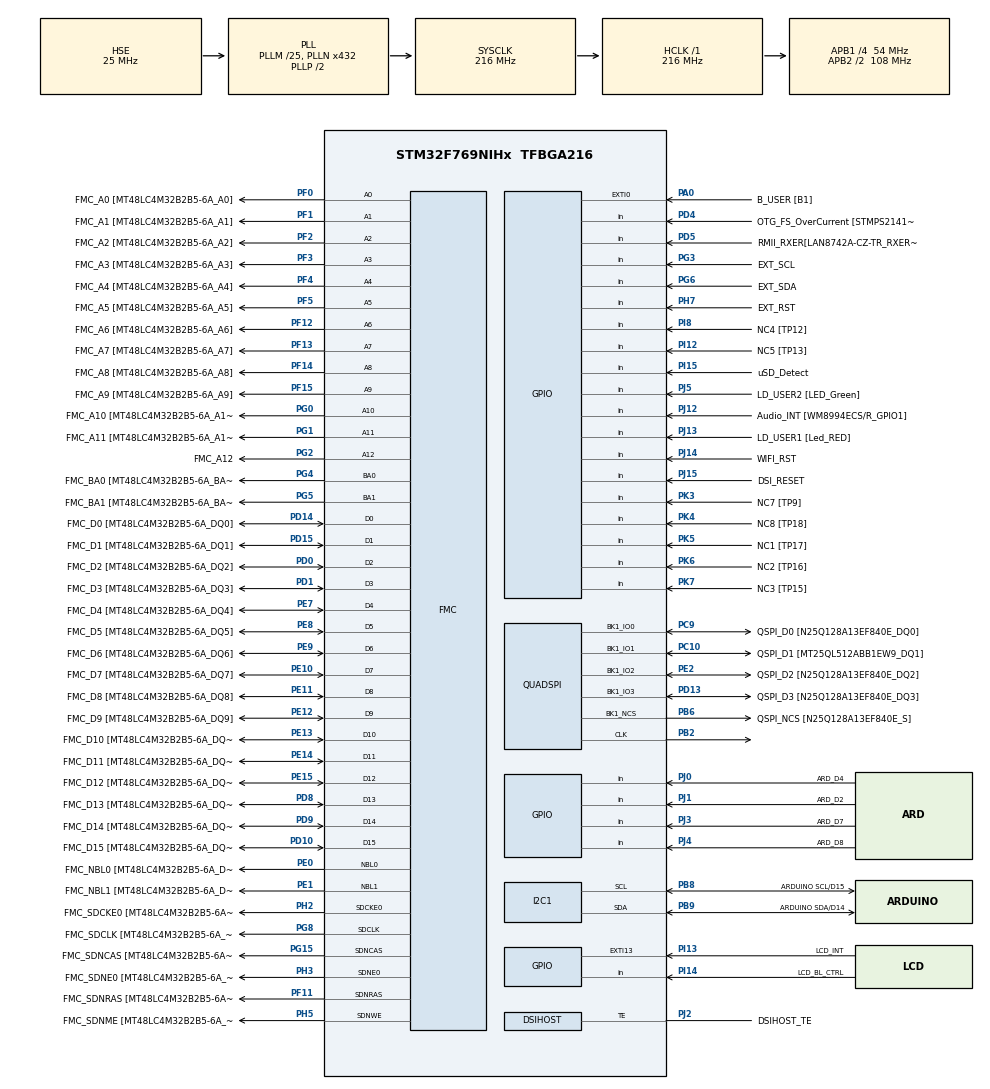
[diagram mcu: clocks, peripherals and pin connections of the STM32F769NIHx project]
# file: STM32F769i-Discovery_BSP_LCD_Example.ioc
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CORTEX_M7.ART_ACCLERATOR_ENABLE=1
CORTEX_M7.CPU_ICache=Enabled
DSIHOST.AcknowledgeRequest=DSI_ACKNOWLEDGE_ENABLE
DSIHOST.CommandSize=800
DSIHOST_CKN.GPIO_Label=DSI_CK_N
DSIHOST_CKN.Mode=DSIHost_Adapted_TE
DSIHOST_CKN.Signal=DSIHOST_CKN
DSIHOST_CKP.GPIO_Label=DSI_CK_P
DSIHOST_CKP.Mode=DSIHost_Adapted_TE
DSIHOST_CKP.Signal=DSIHOST_CKP
DSIHOST_D0N.GPIO_Label=DSI_D0_N
DSIHOST_D0N.Mode=DSIHost_Adapted_TE
DSIHOST_D0N.Signal=DSIHOST_D0N
DSIHOST_D0P.GPIO_Label=DSI_D0_p
DSIHOST_D0P.Mode=DSIHost_Adapted_TE
DSIHOST_D0P.Signal=DSIHOST_D0P
DSIHOST_D1N.GPIO_Label=DSI_D1_N
DSIHOST_D1N.Mode=DSIHost_Adapted_TE
DSIHOST_D1N.Signal=DSIHOST_D1N
DSIHOST_D1P.GPIO_Label=DSI_D1_P
DSIHOST_D1P.Mode=DSIHost_Adapted_TE
DSIHOST_D1P.Signal=DSIHOST_D1P
I2C1.Timing=0x20404768
LTDC.Alpha0_L0=255
LTDC.Alpha0_L1=255
LTDC.WindowX1_L0=800
LTDC.WindowX1_L1=800
LTDC.WindowY1_L0=480
LTDC.WindowY1_L1=480
Mcu.Family=STM32F7
Mcu.Name=STM32F769NIHx
Mcu.Package=TFBGA216
NVIC.EXTI0_IRQn=true\:0\:0\:false\:false\:true\:true\:true
NVIC.PriorityGroup=NVIC_PRIORITYGROUP_4
NVIC.TIM6_DAC_IRQn=true\:0\:0\:false\:false\:true\:false\:true
NVIC.TimeBase=TIM6_DAC_IRQn
NVIC.TimeBaseIP=TIM6
PA0/WKUP.GPIO_Label=B_USER [B1]
PA0/WKUP.Signal=GPXTI0
PA1.GPIO_Label=RMII_REF_CLK [LAN8742A-CZ-TR_REFCLK0]
PA1.Signal=ETH_REF_CLK
PA10.GPIO_Label=VCP_RX 
PA10.Signal=USART1_RX
PA11.GPIO_Label=SPI2_NSS
PA11.Signal=SPI2_NSS
PA12.GPIO_Label=ARD_D13/SCK
PA12.GPIO_Mode=GPIO_MODE_AF_PP
PA12.GPIO_PuPd=GPIO_NOPULL
PA12.GPIO_Speed=GPIO_SPEED_FREQ_LOW
PA12.Signal=SPI2_SCK
PA13.GPIO_Label=SWDIO
PA13.Mode=Serial_Wire
PA13.Signal=SYS_JTMS-SWDIO
PA14.GPIO_Label=SWCLK
PA14.Mode=Serial_Wire
PA14.Signal=SYS_JTCK-SWCLK
PA15.GPIO_Label=CEC
PA15.Signal=CEC
PA2.GPIO_Label=RMII_MDIO [LAN8742A-CZ-TR_MDIO]
PA2.Signal=ETH_MDIO
PA3.GPIO_Label=ULPI_D0 [USB3320C-EZK_D0]
PA3.Signal=USB_OTG_HS_ULPI_D0
PA4.GPIO_Label=ARD_A1
PA4.Signal=ADCx_IN4
PA5.GPIO_Label=ULPI_CLK [USB3320C-EZK_CLKOUT]
PA5.Signal=USB_OTG_HS_ULPI_CK
PA6.GPIO_Label=ARD_A0
PA6.Signal=ADCx_IN6
PA7.GPIO_Label=RMII_CRS_DV [LAN8742A-CZ-TR_CRS_DV]
PA7.Signal=ETH_CRS_DV
PA8.GPIO_Label=CEC_CLK [TP2]
PA8.Signal=RCC_MCO_1
PA9.GPIO_Label=VCP_TX [STM32F103CBT6_PA3]
PA9.GPIO_Mode=GPIO_MODE_AF_PP
PA9.GPIO_PuPd=GPIO_NOPULL
PA9.GPIO_Speed=GPIO_SPEED_FREQ_LOW
PA9.Signal=USART1_TX
PB0.GPIO_Label=ULPI_D1 [USB3320C-EZK_D1]
PB0.Signal=USB_OTG_HS_ULPI_D1
PB1.GPIO_Label=ULPI_D2 [USB3320C-EZK_D2]
PB1.Signal=USB_OTG_HS_ULPI_D2
PB10.GPIO_Label=ULPI_D3 [USB3320C-EZK_D3]
PB10.Signal=USB_OTG_HS_ULPI_D3
PB11.GPIO_Label=ULPI_D4 [USB3320C-EZK_D4]
PB11.Signal=USB_OTG_HS_ULPI_D4
PB12.GPIO_Label=ULPI_D5 [USB3320C-EZK_D5]
PB12.Signal=USB_OTG_HS_ULPI_D5
PB13.GPIO_Label=ULPI_D6 [USB3320C-EZK_D6]
PB13.Signal=USB_OTG_HS_ULPI_D6
PB14.GPIO_Label=ARDUINO MISO/D12
PB14.GPIO_Mode=GPIO_MODE_AF_PP
PB14.GPIO_PuPd=GPIO_NOPULL
PB14.GPIO_Speed=GPIO_SPEED_FREQ_LOW
PB14.Signal=SPI2_MISO
PB15.GPIO_Label=ARDUINO MOSI/PWM/D11
PB15.GPIO_Mode=GPIO_MODE_AF_PP
PB15.GPIO_PuPd=GPIO_NOPULL
PB15.GPIO_Speed=GPIO_SPEED_FREQ_LOW
PB15.Signal=SPI2_MOSI
PB2.Mode=Single Bank 1
PB2.Signal=QUADSPI_CLK
PB3.GPIO_Label=uSD_D2
PB3.Signal=SDMMC2_D2
PB4.GPIO_Label=uSD_D3
PB4.Signal=SDMMC2_D3
PB5.GPIO_Label=ULPI_D7 [USB3320C-EZK_D7]
PB5.Signal=USB_OTG_HS_ULPI_D7
PB6.GPIO_Label=QSPI_NCS [N25Q128A13EF840E_S]
PB6.Mode=Single Bank 1
PB6.Signal=QUADSPI_BK1_NCS
PB7.GPIO_Label=AUDIO_SDA [WM8994ECS/R_SDA]
PB7.Signal=I2C4_SDA
PB8.GPIO_Label=ARDUINO SCL/D15
PB8.GPIO_Mode=GPIO_MODE_AF_OD
PB8.GPIO_PuPd=GPIO_NOPULL
PB8.GPIO_Speed=GPIO_SPEED_FREQ_LOW
PB8.Mode=I2C
PB8.Signal=I2C1_SCL
PB9.GPIO_Label=ARDUINO SDA/D14
PB9.GPIO_Mode=GPIO_MODE_AF_OD
PB9.GPIO_PuPd=GPIO_NOPULL
PB9.GPIO_Speed=GPIO_SPEED_FREQ_LOW
PB9.Mode=I2C
PB9.Signal=I2C1_SDA
PC0.GPIO_Label=ULPI_STP [USB3320C-EZK_STP]
PC0.Signal=USB_OTG_HS_ULPI_STP
PC1.GPIO_Label=RMII_MDC [LAN8742A-CZ-TR_MDC]
PC1.Signal=ETH_MDC
PC10.GPIO_Label=QSPI_D1 [MT25QL512ABB1EW9_DQ1]
PC10.Mode=Single Bank 1
PC10.Signal=QUADSPI_BK1_IO1
PC11.GPIO_Label=DFSDM_DATIN5 [TP100]
PC11.Signal=S_DATAIN5DFSDM1
PC12.GPIO_Label=WIFI_RX
PC12.Signal=UART5_TX
PC13.Signal=RTC_OUT_ALARM
PC14/OSC32_IN.GPIO_Label=RCC_OSC32_IN
PC14/OSC32_IN.Signal=RCC_OSC32_IN
PC15/OSC32_OUT.GPIO_Label=RCC_OSC32_OUT
PC15/OSC32_OUT.Signal=RCC_OSC32_OUT
PC2.GPIO_Label=ARD_A2
PC2.Signal=ADCx_IN12
PC3.GPIO_Label=DFSDM_DATIN1 [TP101]
PC3.Signal=S_DATAIN1DFSDM1
PC4.GPIO_Label=RMII_RXD0 [LAN8742A-CZ-TR_RXD0]
PC4.Signal=ETH_RXD0
PC5.GPIO_Label=RMII_RXD1 [LAN8742A-CZ-TR_RXD1]
PC5.Signal=ETH_RXD1
PC6.GPIO_Label=ARDUINO TX/D1
PC6.Signal=USART6_TX
PC7.GPIO_Label=ARD_D0/RX
PC7.Signal=USART6_RX
PC8.GPIO_Label=ARD_D5/PWM
PC8.Signal=S_TIM3_CH3
PC9.GPIO_Label=QSPI_D0 [N25Q128A13EF840E_DQ0]
PC9.Mode=Single Bank 1
PC9.Signal=QUADSPI_BK1_IO0
PD0.GPIO_Label=FMC_D2 [MT48LC4M32B2B5-6A_DQ2]
PD0.Signal=FMC_D2_DA2
PD1.GPIO_Label=FMC_D3 [MT48LC4M32B2B5-6A_DQ3]
PD1.Signal=FMC_D3_DA3
PD10.GPIO_Label=FMC_D15 [MT48LC4M32B2B5-6A_DQ15]
PD10.Signal=FMC_D15_DA15
PD11.GPIO_Label=SPDIF_TX [TP20]
PD11.Signal=SAI2_SD_A
PD12.GPIO_Label=AUDIO_SCL [WM8994ECS/R_SCLK]
PD12.Signal=I2C4_SCL
PD13.GPIO_Label=QSPI_D3 [N25Q128A13EF840E_DQ3]
PD13.Mode=Single Bank 1
PD13.Signal=QUADSPI_BK1_IO3
PD14.GPIO_Label=FMC_D0 [MT48LC4M32B2B5-6A_DQ0]
PD14.Signal=FMC_D0_DA0
PD15.GPIO_Label=FMC_D1 [MT48LC4M32B2B5-6A_DQ1]
PD15.Signal=FMC_D1_DA1
PD2.GPIO_Label=WIFI_TX
PD2.Signal=UART5_RX
PD3.GPIO_Label=DFSDM_CKOUT [TP102]
PD3.Signal=S_CKOUTDFSDM1
PD4.GPIO_Label=OTG_FS_OverCurrent [STMPS2141STR_Fault]
PD4.Signal=GPIO_Input
PD5.GPIO_Label=RMII_RXER[LAN8742A-CZ-TR_RXERR]
PD5.Signal=GPIO_Input
PD6.GPIO_Label=uSD_CLK
PD6.Signal=SDMMC2_CK
PD7.GPIO_Label=uSD_CMD
PD7.Signal=SDMMC2_CMD
PD8.GPIO_Label=FMC_D13 [MT48LC4M32B2B5-6A_DQ13]
PD8.Signal=FMC_D13_DA13
PD9.GPIO_Label=FMC_D14 [MT48LC4M32B2B5-6A_DQ14]
PD9.Signal=FMC_D14_DA14
PE0.GPIO_Label=FMC_NBL0 [MT48LC4M32B2B5-6A_DQM0]
PE0.Signal=FMC_NBL0
PE1.GPIO_Label=FMC_NBL1 [MT48LC4M32B2B5-6A_DQM1]
PE1.Signal=FMC_NBL1
PE10.GPIO_Label=FMC_D7 [MT48LC4M32B2B5-6A_DQ7]
PE10.Signal=FMC_D7_DA7
PE11.GPIO_Label=FMC_D8 [MT48LC4M32B2B5-6A_DQ8]
PE11.Signal=FMC_D8_DA8
PE12.GPIO_Label=FMC_D9 [MT48LC4M32B2B5-6A_DQ9]
PE12.Signal=FMC_D9_DA9
PE13.GPIO_Label=FMC_D10 [MT48LC4M32B2B5-6A_DQ10]
PE13.Signal=FMC_D10_DA10
PE14.GPIO_Label=FMC_D11 [MT48LC4M32B2B5-6A_DQ11]
PE14.Signal=FMC_D11_DA11
PE15.GPIO_Label=FMC_D12 [MT48LC4M32B2B5-6A_DQ12]
PE15.Signal=FMC_D12_DA12
PE2.GPIO_Label=QSPI_D2 [N25Q128A13EF840E_DQ2]
PE2.Mode=Single Bank 1
PE2.Signal=QUADSPI_BK1_IO2
PE3.GPIO_Label=SAI1_SDB [WM8994ECS/R_ADCDAT1]
PE3.Signal=SAI1_SD_B
PE4.GPIO_Label=SAI1_FSA [WM8994ECS/R_LRCLK1]
PE4.Signal=SAI1_FS_A
PE5.GPIO_Label=SAI1_SCKA [WM8994ECS/R_BCLK1]
PE5.Signal=SAI1_SCK_A
PE6.GPIO_Label=SAI1_SDA [WM8994ECS/R_DACDAT1]
PE6.Signal=SAI1_SD_A
PE7.GPIO_Label=FMC_D4 [MT48LC4M32B2B5-6A_DQ4]
PE7.Signal=FMC_D4_DA4
PE8.GPIO_Label=FMC_D5 [MT48LC4M32B2B5-6A_DQ5]
PE8.Signal=FMC_D5_DA5
PE9.GPIO_Label=FMC_D6 [MT48LC4M32B2B5-6A_DQ6]
PE9.Signal=FMC_D6_DA6
PF0.GPIO_Label=FMC_A0 [MT48LC4M32B2B5-6A_A0]
PF0.Signal=FMC_A0
PF1.GPIO_Label=FMC_A1 [MT48LC4M32B2B5-6A_A1]
PF1.Signal=FMC_A1
PF10.GPIO_Label=ARDUINO A1
PF10.GPIO_Mode=GPIO_MODE_ANALOG
PF10.GPIO_PuPd=GPIO_NOPULL
PF10.Signal=ADC3_IN8
PF11.GPIO_Label=FMC_SDNRAS [MT48LC4M32B2B5-6A_RAS]
PF11.Signal=FMC_SDNRAS
PF12.GPIO_Label=FMC_A6 [MT48LC4M32B2B5-6A_A6]
PF12.Signal=FMC_A6
PF13.GPIO_Label=FMC_A7 [MT48LC4M32B2B5-6A_A7]
PF13.Signal=FMC_A7
PF14.GPIO_Label=FMC_A8 [MT48LC4M32B2B5-6A_A8]
PF14.Signal=FMC_A8
PF15.GPIO_Label=FMC_A9 [MT48LC4M32B2B5-6A_A9]
PF15.Signal=FMC_A9
PF2.GPIO_Label=FMC_A2 [MT48LC4M32B2B5-6A_A2]
PF2.Signal=FMC_A2
PF3.GPIO_Label=FMC_A3 [MT48LC4M32B2B5-6A_A3]
PF3.Signal=FMC_A3
PF4.GPIO_Label=FMC_A4 [MT48LC4M32B2B5-6A_A4]
PF4.Signal=FMC_A4
PF5.GPIO_Label=FMC_A5 [MT48LC4M32B2B5-6A_A5]
PF5.Signal=FMC_A5
PF6.GPIO_Label=ARD_D3/PWM
PF6.Signal=S_TIM10_CH1
PF7.GPIO_Label=ARD_D6/PWM
PF7.Signal=S_TIM11_CH1
PF8.GPIO_Label=ARDUINO A3
PF8.GPIO_Mode=GPIO_MODE_ANALOG
PF8.GPIO_PuPd=GPIO_NOPULL
PF8.Signal=ADC3_IN6
PF9.GPIO_Label=ARDUINO A2
PF9.GPIO_Mode=GPIO_MODE_ANALOG
PF9.GPIO_PuPd=GPIO_NOPULL
PF9.Signal=ADC3_IN7
PG0.GPIO_Label=FMC_A10 [MT48LC4M32B2B5-6A_A10]
PG0.Signal=FMC_A10
PG1.GPIO_Label=FMC_A11 [MT48LC4M32B2B5-6A_A11]
PG1.Signal=FMC_A11
PG10.GPIO_Label=uSD_D1
PG10.Signal=SDMMC2_D1
PG11.GPIO_Label=RMII_TX_EN [LAN8742A-CZ-TR_TXEN]
PG11.Signal=ETH_TX_EN
PG12.GPIO_Label=SPDIF_RX [74LVC1G04SE_4]
PG12.Signal=SPDIFRX_IN1
PG13.GPIO_Label=RMII_TXD0 [LAN8742A-CZ-TR_TXD0]
PG13.Signal=ETH_TXD0
PG14.GPIO_Label=RMII_TXD1 [LAN8742A-CZ-TR_TXD1]
PG14.Signal=ETH_TXD1
PG15.GPIO_Label=FMC_SDNCAS [MT48LC4M32B2B5-6A_CAS]
PG15.Signal=FMC_SDNCAS
PG2.GPIO_Label=FMC_A12
PG2.Signal=FMC_A12
PG3.GPIO_Label=EXT_SCL
PG3.Signal=GPIO_Input
PG4.GPIO_Label=FMC_BA0 [MT48LC4M32B2B5-6A_BA0]
PG4.Signal=FMC_A14_BA0
PG5.GPIO_Label=FMC_BA1 [MT48LC4M32B2B5-6A_BA1]
PG5.Signal=FMC_A15_BA1
PG6.GPIO_Label=EXT_SDA
PG6.Signal=GPIO_Input
PG7.GPIO_Label=SAI1_MCLKA [WM8994ECS/R_MCLK1]
PG7.Signal=SAI1_MCLK_A
PG8.GPIO_Label=FMC_SDCLK [MT48LC4M32B2B5-6A_CLK]
PG8.Signal=FMC_SDCLK
PG9.GPIO_Label=uSD_D0
PG9.Signal=SDMMC2_D0
PH0/OSC_IN.GPIO_Label=OSC_25M [NZ2520SB-25.00M_OUT]
PH0/OSC_IN.Mode=HSE-External-Oscillator
PH0/OSC_IN.Signal=RCC_OSC_IN
PH1/OSC_OUT.Mode=HSE-External-Oscillator
PH1/OSC_OUT.Signal=RCC_OSC_OUT
PH10.GPIO_Label=FMC_D18 [MT48LC4M32B2B5-6A_DQ18]
PH10.Signal=FMC_D18
PH11.GPIO_Label=FMC_D19 [MT48LC4M32B2B5-6A_DQ19]
PH11.Signal=FMC_D19
PH12.GPIO_Label=D20
PH12.Signal=FMC_D20
PH13.GPIO_Label=D21
PH13.Signal=FMC_D21
PH14.GPIO_Label=D22
PH14.Signal=FMC_D22
PH15.GPIO_Label=D23
PH15.Signal=FMC_D23
PH2.GPIO_Label=FMC_SDCKE0 [MT48LC4M32B2B5-6A_CKE]
PH2.Mode=SdramChipSelect1_1
PH2.Signal=FMC_SDCKE0
PH3.GPIO_Label=FMC_SDNE0 [MT48LC4M32B2B5-6A_CS]
PH3.Mode=SdramChipSelect1_1
PH3.Signal=FMC_SDNE0
PH4.GPIO_Label=ULPI_NXT [USB3320C-EZK_NXT]
PH4.Signal=USB_OTG_HS_ULPI_NXT
PH5.GPIO_Label=FMC_SDNME [MT48LC4M32B2B5-6A_WE]
PH5.Signal=FMC_SDNWE
PH6.GPIO_Label=ARDUINO PWM/D6
PH6.Signal=S_TIM12_CH1
PH7.GPIO_Label=EXT_RST
PH7.Signal=GPIO_Input
PH8.GPIO_Label=FMC_D16 [MT48LC4M32B2B5-6A_DQ16]
PH8.Signal=FMC_D16
PH9.GPIO_Label=FMC_D\!7 [MT48LC4M32B2B5-6A_DQ17]
PH9.Signal=FMC_D17
PI0.GPIO_Label=D24
PI0.Signal=FMC_D24
PI1.GPIO_Label=D25
PI1.Signal=FMC_D25
PI10.GPIO_Label=D31
PI10.Signal=FMC_D31
PI11.GPIO_Label=ULPI_DIR [USB3320C-EZK_DIR]
PI11.Signal=USB_OTG_HS_ULPI_DIR
PI12.GPIO_Label=NC5 [TP13]
PI12.Signal=GPIO_Input
PI13.GPIO_Label=LCD_INT
PI13.GPIO_ModeDefaultEXTI=GPIO_MODE_EVT_RISING
PI13.Signal=GPXTI13
PI14.GPIO_Label=LCD_BL_CTRL
PI14.Signal=GPIO_Input
PI15.GPIO_Label=uSD_Detect
PI15.Signal=GPIO_Input
PI2.GPIO_Label=D26
PI2.Signal=FMC_D26
PI3.GPIO_Label=D27
PI3.Signal=FMC_D27
PI4.GPIO_Label=FMC_NBL2 [MT48LC4M32B2B5-6A_DQM2]
PI4.Signal=FMC_NBL2
PI5.GPIO_Label=FMC_NBL3 [MT48LC4M32B2B5-6A_DQM3]
PI5.Signal=FMC_NBL3
PI6.GPIO_Label=D28
PI6.Signal=FMC_D28
PI7.GPIO_Label=D29
PI7.Signal=FMC_D29
PI8.GPIO_Label=NC4 [TP12]
PI8.Signal=GPIO_Input
PI9.GPIO_Label=D30
PI9.Signal=FMC_D30
PJ0.GPIO_Label=ARD_D4
PJ0.Signal=GPIO_Input
PJ1.GPIO_Label=ARD_D2
PJ1.Signal=GPIO_Input
PJ12.GPIO_Label=Audio_INT [WM8994ECS/R_GPIO1]
PJ12.Signal=GPIO_Input
PJ13.GPIO_Label=LD_USER1 [Led_RED]
PJ13.Signal=GPIO_Input
PJ14.GPIO_Label=WIFI_RST
PJ14.Signal=GPIO_Input
PJ15.GPIO_Label=DSI_RESET
PJ15.Signal=GPIO_Input
PJ2.GPIO_Label=DSIHOST_TE
PJ2.Mode=DSIHost_Adapted_TE
PJ2.Signal=DSIHOST_TE
PJ3.GPIO_Label=ARD_D7
PJ3.Signal=GPIO_Input
PJ4.GPIO_Label=ARD_D8
PJ4.Signal=GPIO_Input
PJ5.GPIO_Label=LD_USER2 [LED_Green]
PJ5.Signal=GPIO_Input
PK3.GPIO_Label=NC7 [TP9]
PK3.Signal=GPIO_Input
PK4.GPIO_Label=NC8 [TP18]
PK4.Signal=GPIO_Input
PK5.GPIO_Label=NC1 [TP17]
PK5.Signal=GPIO_Input
PK6.GPIO_Label=NC2 [TP16]
PK6.Signal=GPIO_Input
PK7.GPIO_Label=NC3 [TP15]
PK7.Signal=GPIO_Input
ProjectManager.HeapSize=0x2000
ProjectManager.StackSize=0x4000
ProjectManager.TargetToolchain=STM32CubeIDE
RCC.AHBFreq_Value=216000000
RCC.APB1CLKDivider=RCC_HCLK_DIV4
RCC.APB1Freq_Value=54000000
RCC.APB1TimFreq_Value=108000000
RCC.APB2CLKDivider=RCC_HCLK_DIV2
RCC.APB2Freq_Value=108000000
RCC.APB2TimFreq_Value=216000000
RCC.CortexFreq_Value=216000000
RCC.HCLKFreq_Value=216000000
RCC.HSE_VALUE=25000000
RCC.HSI_VALUE=16000000
RCC.LSE_VALUE=32768
RCC.PLLM=25
RCC.PLLN=432
RCC.PLLQ=4
RCC.PLLSAIQ=3
RCC.PLLSourceVirtual=RCC_PLLSOURCE_HSE
RCC.SYSCLKFreq_VALUE=216000000
RCC.SYSCLKSource=RCC_SYSCLKSOURCE_PLLCLK
RCC.USBFreq_Value=108000000
RCC.VCOOutputFreq_Value=432000000
SH.ADCx_IN12.0=ADC1_IN12
SH.ADCx_IN4.0=ADC1_IN4
SH.ADCx_IN6.0=ADC1_IN6
SH.FMC_A0.0=FMC_A0,13b-sda1
SH.FMC_A1.0=FMC_A1,13b-sda1
SH.FMC_A10.0=FMC_A10,13b-sda1
SH.FMC_A11.0=FMC_A11,13b-sda1
SH.FMC_A12.0=FMC_A12,13b-sda1
SH.FMC_A14_BA0.0=FMC_BA0,FourSdramBanks1
SH.FMC_A15_BA1.0=FMC_BA1,FourSdramBanks1
SH.FMC_A2.0=FMC_A2,13b-sda1
SH.FMC_A3.0=FMC_A3,13b-sda1
SH.FMC_A4.0=FMC_A4,13b-sda1
SH.FMC_A5.0=FMC_A5,13b-sda1
SH.FMC_A6.0=FMC_A6,13b-sda1
SH.FMC_A7.0=FMC_A7,13b-sda1
SH.FMC_A8.0=FMC_A8,13b-sda1
SH.FMC_A9.0=FMC_A9,13b-sda1
SH.FMC_D0_DA0.0=FMC_D0,sd-16b-d1
SH.FMC_D10_DA10.0=FMC_D10,sd-16b-d1
SH.FMC_D11_DA11.0=FMC_D11,sd-16b-d1
SH.FMC_D12_DA12.0=FMC_D12,sd-16b-d1
SH.FMC_D13_DA13.0=FMC_D13,sd-16b-d1
SH.FMC_D14_DA14.0=FMC_D14,sd-16b-d1
SH.FMC_D15_DA15.0=FMC_D15,sd-16b-d1
SH.FMC_D16.0=FMC_D16
SH.FMC_D17.0=FMC_D17
SH.FMC_D18.0=FMC_D18
SH.FMC_D19.0=FMC_D19
SH.FMC_D1_DA1.0=FMC_D1,sd-16b-d1
SH.FMC_D20.0=FMC_D20
SH.FMC_D21.0=FMC_D21
SH.FMC_D22.0=FMC_D22
SH.FMC_D23.0=FMC_D23
SH.FMC_D24.0=FMC_D24
SH.FMC_D25.0=FMC_D25
SH.FMC_D26.0=FMC_D26
SH.FMC_D27.0=FMC_D27
SH.FMC_D28.0=FMC_D28
SH.FMC_D29.0=FMC_D29
SH.FMC_D2_DA2.0=FMC_D2,sd-16b-d1
SH.FMC_D30.0=FMC_D30
SH.FMC_D31.0=FMC_D31
SH.FMC_D3_DA3.0=FMC_D3,sd-16b-d1
SH.FMC_D4_DA4.0=FMC_D4,sd-16b-d1
SH.FMC_D5_DA5.0=FMC_D5,sd-16b-d1
SH.FMC_D6_DA6.0=FMC_D6,sd-16b-d1
SH.FMC_D7_DA7.0=FMC_D7,sd-16b-d1
SH.FMC_D8_DA8.0=FMC_D8,sd-16b-d1
SH.FMC_D9_DA9.0=FMC_D9,sd-16b-d1
SH.FMC_NBL0.0=FMC_NBL0,Sd2ByteEnable1
SH.FMC_NBL1.0=FMC_NBL1,Sd2ByteEnable1
SH.FMC_NBL2.0=FMC_NBL2
SH.FMC_NBL3.0=FMC_NBL3
SH.FMC_SDCLK.0=FMC_SDCLK,13b-sda1
SH.FMC_SDNCAS.0=FMC_SDNCAS,13b-sda1
SH.FMC_SDNRAS.0=FMC_SDNRAS,13b-sda1
SH.FMC_SDNWE.0=FMC_SDNWE,13b-sda1
SH.S_CKOUTDFSDM1.0=DFSDM1_CKOUT
SH.S_DATAIN1DFSDM1.0=DFSDM1_DATIN1
SH.S_DATAIN5DFSDM1.0=DFSDM1_DATIN5
SH.S_TIM10_CH1.0=TIM10_CH1
SH.S_TIM11_CH1.0=TIM11_CH1
SH.S_TIM12_CH1.0=TIM12_CH1
SH.S_TIM3_CH3.0=TIM3_CH3
VP_CRC_VS_CRC.Mode=CRC_Activate
VP_DMA2D_VS_DMA2D.Mode=DMA2D_Activate
VP_LTDC_DSIMode.Mode=RGB888
VP_SYS_VS_tim6.Mode=TIM6
board=STM32F769I-DISCO

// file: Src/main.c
/* USER CODE BEGIN Header */
/**
  ******************************************************************************
  * @file           : main.c
  * @brief          : Main program body
  ******************************************************************************
  * @attention
  *
  * <h2><center>&copy; Copyright (c) 2019 STMicroelectronics.
  * All rights reserved.</center></h2>
  *
  * This software component is licensed by ST under BSD 3-Clause license,
  * the "License"; You may not use this file except in compliance with the
  * License. You may obtain a copy of the License at:
  *                        opensource.org/licenses/BSD-3-Clause
  *
  ******************************************************************************
  */
/* USER CODE END Header */

#include "main.h"

/* USER CODE BEGIN Includes */
#include "stm32f769i_discovery_lcd.h"
#include "stm32f769i_discovery_ts.h"
#include "stm32f769i_discovery.h"
#include "fonts.h"
#include "stm32f769i_discovery_sdram.h"
#include "stm32f7xx_hal.h"
#include "stm32F769i_discovery_qspi.h"
#include "stm32f769i_discovery_eeprom.h"

/* USER CODE END Includes */

CRC_HandleTypeDef hcrc;

DMA2D_HandleTypeDef hdma2d;

DSI_HandleTypeDef hdsi;

I2C_HandleTypeDef hi2c1;

LTDC_HandleTypeDef hltdc;

QSPI_HandleTypeDef hqspi;

SDRAM_HandleTypeDef hsdram1;

void SystemClock_Config(void);
static void MX_GPIO_Init(void);
static void MX_CRC_Init(void);
static void MX_DMA2D_Init(void);
static void MX_DSIHOST_DSI_Init(void);
static void MX_FMC_Init(void);
static void MX_LTDC_Init(void);
static void MX_QUADSPI_Init(void);
static void MX_I2C1_Init(void);

int main(void)
{

  /* Enable I-Cache---------------------------------------------------------*/
  SCB_EnableICache();

  /* MCU Configuration--------------------------------------------------------*/

  /* Reset of all peripherals, Initializes the Flash interface and the Systick. */
  HAL_Init();

  /* Configure the system clock */
  SystemClock_Config();

  /* Initialize all configured peripherals */
  MX_GPIO_Init();
  MX_CRC_Init();
  MX_DMA2D_Init();
  MX_DSIHOST_DSI_Init();
  MX_FMC_Init();
  MX_LTDC_Init();
  MX_QUADSPI_Init();
  MX_I2C1_Init();

  /* USER CODE BEGIN 2 */
  BSP_LCD_Init();
  BSP_TS_Init(800,480);

  BSP_LCD_LayerDefaultInit(0, 0xC0000000);
  BSP_LCD_SelectLayer(0);
  BSP_LCD_DisplayOn();
  BSP_LCD_Clear(LCD_COLOR_BLACK);
  BSP_LCD_SetBackColor(LCD_COLOR_BLACK);
  BSP_LCD_SetTextColor(LCD_COLOR_WHITE);
  BSP_LCD_SetFont(&Font24);
  BSP_LCD_DisplayStringAt(10, 300,"Hello", CENTER_MODE);
  /* USER CODE END 2 */

  /* Infinite loop */
  /* USER CODE BEGIN WHILE */
  while (1)
  {

//BSP_LCD_DisplayStringAt(10, 300,"Hello", CENTER_MODE);

//	  BSP_LED_Toggle(LED1);
//	  HAL_Delay(250);

    /* USER CODE END WHILE */

  }
}

void SystemClock_Config(void)
{
  RCC_OscInitTypeDef RCC_OscInitStruct = {0};
  RCC_ClkInitTypeDef RCC_ClkInitStruct = {0};
  RCC_PeriphCLKInitTypeDef PeriphClkInitStruct = {0};

  /** Configure the main internal regulator output voltage
  */
  __HAL_RCC_PWR_CLK_ENABLE();
  __HAL_PWR_VOLTAGESCALING_CONFIG(PWR_REGULATOR_VOLTAGE_SCALE1);
  /** Initializes the CPU, AHB and APB busses clocks
  */
  RCC_OscInitStruct.OscillatorType = RCC_OSCILLATORTYPE_HSE;
  RCC_OscInitStruct.HSEState = RCC_HSE_ON;
  RCC_OscInitStruct.PLL.PLLState = RCC_PLL_ON;
  RCC_OscInitStruct.PLL.PLLSource = RCC_PLLSOURCE_HSE;
  RCC_OscInitStruct.PLL.PLLM = 25;
  RCC_OscInitStruct.PLL.PLLN = 432;
  RCC_OscInitStruct.PLL.PLLP = RCC_PLLP_DIV2;
  RCC_OscInitStruct.PLL.PLLQ = 4;
  if (HAL_RCC_OscConfig(&RCC_OscInitStruct) != HAL_OK)
  {
    Error_Handler();
  }
  /** Activate the Over-Drive mode
  */
  if (HAL_PWREx_EnableOverDrive() != HAL_OK)
  {
    Error_Handler();
  }
  /** Initializes the CPU, AHB and APB busses clocks
  */
  RCC_ClkInitStruct.ClockType = RCC_CLOCKTYPE_HCLK|RCC_CLOCKTYPE_SYSCLK
                              |RCC_CLOCKTYPE_PCLK1|RCC_CLOCKTYPE_PCLK2;
  RCC_ClkInitStruct.SYSCLKSource = RCC_SYSCLKSOURCE_PLLCLK;
  RCC_ClkInitStruct.AHBCLKDivider = RCC_SYSCLK_DIV1;
  RCC_ClkInitStruct.APB1CLKDivider = RCC_HCLK_DIV4;
  RCC_ClkInitStruct.APB2CLKDivider = RCC_HCLK_DIV2;

  if (HAL_RCC_ClockConfig(&RCC_ClkInitStruct, FLASH_LATENCY_7) != HAL_OK)
  {
    Error_Handler();
  }
  PeriphClkInitStruct.PeriphClockSelection = RCC_PERIPHCLK_LTDC|RCC_PERIPHCLK_I2C1;
  PeriphClkInitStruct.PLLSAI.PLLSAIN = 192;
  PeriphClkInitStruct.PLLSAI.PLLSAIR = 2;
  PeriphClkInitStruct.PLLSAI.PLLSAIQ = 3;
  PeriphClkInitStruct.PLLSAI.PLLSAIP = RCC_PLLSAIP_DIV2;
  PeriphClkInitStruct.PLLSAIDivQ = 1;
  PeriphClkInitStruct.PLLSAIDivR = RCC_PLLSAIDIVR_2;
  PeriphClkInitStruct.I2c1ClockSelection = RCC_I2C1CLKSOURCE_PCLK1;
  if (HAL_RCCEx_PeriphCLKConfig(&PeriphClkInitStruct) != HAL_OK)
  {
    Error_Handler();
  }
}

static void MX_CRC_Init(void)
{

  hcrc.Instance = CRC;
  hcrc.Init.DefaultPolynomialUse = DEFAULT_POLYNOMIAL_ENABLE;
  hcrc.Init.DefaultInitValueUse = DEFAULT_INIT_VALUE_ENABLE;
  hcrc.Init.InputDataInversionMode = CRC_INPUTDATA_INVERSION_NONE;
  hcrc.Init.OutputDataInversionMode = CRC_OUTPUTDATA_INVERSION_DISABLE;
  hcrc.InputDataFormat = CRC_INPUTDATA_FORMAT_BYTES;
  if (HAL_CRC_Init(&hcrc) != HAL_OK)
  {
    Error_Handler();
  }

}

static void MX_DMA2D_Init(void)
{

  hdma2d.Instance = DMA2D;
  hdma2d.Init.Mode = DMA2D_M2M;
  hdma2d.Init.ColorMode = DMA2D_OUTPUT_ARGB8888;
  hdma2d.Init.OutputOffset = 0;
  hdma2d.LayerCfg[1].InputOffset = 0;
  hdma2d.LayerCfg[1].InputColorMode = DMA2D_INPUT_ARGB8888;
  hdma2d.LayerCfg[1].AlphaMode = DMA2D_NO_MODIF_ALPHA;
  hdma2d.LayerCfg[1].InputAlpha = 0;
  hdma2d.LayerCfg[1].AlphaInverted = DMA2D_REGULAR_ALPHA;
  hdma2d.LayerCfg[1].RedBlueSwap = DMA2D_RB_REGULAR;
  if (HAL_DMA2D_Init(&hdma2d) != HAL_OK)
  {
    Error_Handler();
  }
  if (HAL_DMA2D_ConfigLayer(&hdma2d, 1) != HAL_OK)
  {
    Error_Handler();
  }

}

static void MX_DSIHOST_DSI_Init(void)
{

  DSI_PLLInitTypeDef PLLInit = {0};
  DSI_HOST_TimeoutTypeDef HostTimeouts = {0};
  DSI_PHY_TimerTypeDef PhyTimings = {0};
  DSI_LPCmdTypeDef LPCmd = {0};
  DSI_CmdCfgTypeDef CmdCfg = {0};

  hdsi.Instance = DSI;
  hdsi.Init.AutomaticClockLaneControl = DSI_AUTO_CLK_LANE_CTRL_DISABLE;
  hdsi.Init.TXEscapeCkdiv = 4;
  hdsi.Init.NumberOfLanes = DSI_ONE_DATA_LANE;
  PLLInit.PLLNDIV = 20;
  PLLInit.PLLIDF = DSI_PLL_IN_DIV1;
  PLLInit.PLLODF = DSI_PLL_OUT_DIV1;
  if (HAL_DSI_Init(&hdsi, &PLLInit) != HAL_OK)
  {
    Error_Handler();
  }
  HostTimeouts.TimeoutCkdiv = 1;
  HostTimeouts.HighSpeedTransmissionTimeout = 0;
  HostTimeouts.LowPowerReceptionTimeout = 0;
  HostTimeouts.HighSpeedReadTimeout = 0;
  HostTimeouts.LowPowerReadTimeout = 0;
  HostTimeouts.HighSpeedWriteTimeout = 0;
  HostTimeouts.HighSpeedWritePrespMode = DSI_HS_PM_DISABLE;
  HostTimeouts.LowPowerWriteTimeout = 0;
  HostTimeouts.BTATimeout = 0;
  if (HAL_DSI_ConfigHostTimeouts(&hdsi, &HostTimeouts) != HAL_OK)
  {
    Error_Handler();
  }
  PhyTimings.ClockLaneHS2LPTime = 28;
  PhyTimings.ClockLaneLP2HSTime = 33;
  PhyTimings.DataLaneHS2LPTime = 15;
  PhyTimings.DataLaneLP2HSTime = 25;
  PhyTimings.DataLaneMaxReadTime = 0;
  PhyTimings.StopWaitTime = 0;
  if (HAL_DSI_ConfigPhyTimer(&hdsi, &PhyTimings) != HAL_OK)
  {
    Error_Handler();
  }
  if (HAL_DSI_ConfigFlowControl(&hdsi, DSI_FLOW_CONTROL_BTA) != HAL_OK)
  {
    Error_Handler();
  }
  if (HAL_DSI_SetLowPowerRXFilter(&hdsi, 10000) != HAL_OK)
  {
    Error_Handler();
  }
  if (HAL_DSI_ConfigErrorMonitor(&hdsi, HAL_DSI_ERROR_NONE) != HAL_OK)
  {
    Error_Handler();
  }
  LPCmd.LPGenShortWriteNoP = DSI_LP_GSW0P_DISABLE;
  LPCmd.LPGenShortWriteOneP = DSI_LP_GSW1P_DISABLE;
  LPCmd.LPGenShortWriteTwoP = DSI_LP_GSW2P_DISABLE;
  LPCmd.LPGenShortReadNoP = DSI_LP_GSR0P_DISABLE;
  LPCmd.LPGenShortReadOneP = DSI_LP_GSR1P_DISABLE;
  LPCmd.LPGenShortReadTwoP = DSI_LP_GSR2P_DISABLE;
  LPCmd.LPGenLongWrite = DSI_LP_GLW_DISABLE;
  LPCmd.LPDcsShortWriteNoP = DSI_LP_DSW0P_DISABLE;
  LPCmd.LPDcsShortWriteOneP = DSI_LP_DSW1P_DISABLE;
  LPCmd.LPDcsShortReadNoP = DSI_LP_DSR0P_DISABLE;
  LPCmd.LPDcsLongWrite = DSI_LP_DLW_DISABLE;
  LPCmd.LPMaxReadPacket = DSI_LP_MRDP_DISABLE;
  LPCmd.AcknowledgeRequest = DSI_ACKNOWLEDGE_ENABLE;
  if (HAL_DSI_ConfigCommand(&hdsi, &LPCmd) != HAL_OK)
  {
    Error_Handler();
  }
  CmdCfg.VirtualChannelID = 0;
  CmdCfg.ColorCoding = DSI_RGB888;
  CmdCfg.CommandSize = 800;
  CmdCfg.TearingEffectSource = DSI_TE_EXTERNAL;
  CmdCfg.TearingEffectPolarity = DSI_TE_RISING_EDGE;
  CmdCfg.HSPolarity = DSI_HSYNC_ACTIVE_LOW;
  CmdCfg.VSPolarity = DSI_VSYNC_ACTIVE_LOW;
  CmdCfg.DEPolarity = DSI_DATA_ENABLE_ACTIVE_HIGH;
  CmdCfg.VSyncPol = DSI_VSYNC_FALLING;
  CmdCfg.AutomaticRefresh = DSI_AR_ENABLE;
  CmdCfg.TEAcknowledgeRequest = DSI_TE_ACKNOWLEDGE_DISABLE;
  if (HAL_DSI_ConfigAdaptedCommandMode(&hdsi, &CmdCfg) != HAL_OK)
  {
    Error_Handler();
  }
  if (HAL_DSI_SetGenericVCID(&hdsi, 0) != HAL_OK)
  {
    Error_Handler();
  }

}

static void MX_I2C1_Init(void)
{

  hi2c1.Instance = I2C1;
  hi2c1.Init.Timing = 0x20404768;
  hi2c1.Init.OwnAddress1 = 0;
  hi2c1.Init.AddressingMode = I2C_ADDRESSINGMODE_7BIT;
  hi2c1.Init.DualAddressMode = I2C_DUALADDRESS_DISABLE;
  hi2c1.Init.OwnAddress2 = 0;
  hi2c1.Init.OwnAddress2Masks = I2C_OA2_NOMASK;
  hi2c1.Init.GeneralCallMode = I2C_GENERALCALL_DISABLE;
  hi2c1.Init.NoStretchMode = I2C_NOSTRETCH_DISABLE;
  if (HAL_I2C_Init(&hi2c1) != HAL_OK)
  {
    Error_Handler();
  }
  /** Configure Analogue filter
  */
  if (HAL_I2CEx_ConfigAnalogFilter(&hi2c1, I2C_ANALOGFILTER_ENABLE) != HAL_OK)
  {
    Error_Handler();
  }
  /** Configure Digital filter
  */
  if (HAL_I2CEx_ConfigDigitalFilter(&hi2c1, 0) != HAL_OK)
  {
    Error_Handler();
  }

}

static void MX_LTDC_Init(void)
{

  LTDC_LayerCfgTypeDef pLayerCfg = {0};
  LTDC_LayerCfgTypeDef pLayerCfg1 = {0};

  hltdc.Instance = LTDC;
  hltdc.Init.HSPolarity = LTDC_HSPOLARITY_AL;
  hltdc.Init.VSPolarity = LTDC_VSPOLARITY_AL;
  hltdc.Init.DEPolarity = LTDC_DEPOLARITY_AL;
  hltdc.Init.PCPolarity = LTDC_PCPOLARITY_IPC;
  hltdc.Init.HorizontalSync = 7;
  hltdc.Init.VerticalSync = 3;
  hltdc.Init.AccumulatedHBP = 14;
  hltdc.Init.AccumulatedVBP = 5;
  hltdc.Init.AccumulatedActiveW = 654;
  hltdc.Init.AccumulatedActiveH = 485;
  hltdc.Init.TotalWidth = 660;
  hltdc.Init.TotalHeigh = 487;
  hltdc.Init.Backcolor.Blue = 0;
  hltdc.Init.Backcolor.Green = 0;
  hltdc.Init.Backcolor.Red = 0;
  if (HAL_LTDC_Init(&hltdc) != HAL_OK)
  {
    Error_Handler();
  }
  pLayerCfg.WindowX0 = 0;
  pLayerCfg.WindowX1 = 800;
  pLayerCfg.WindowY0 = 0;
  pLayerCfg.WindowY1 = 480;
  pLayerCfg.PixelFormat = LTDC_PIXEL_FORMAT_ARGB8888;
  pLayerCfg.Alpha = 0;
  pLayerCfg.Alpha0 = 255;
  pLayerCfg.BlendingFactor1 = LTDC_BLENDING_FACTOR1_CA;
  pLayerCfg.BlendingFactor2 = LTDC_BLENDING_FACTOR2_CA;
  pLayerCfg.FBStartAdress = 0;
  pLayerCfg.ImageWidth = 0;
  pLayerCfg.ImageHeight = 0;
  pLayerCfg.Backcolor.Blue = 0;
  pLayerCfg.Backcolor.Green = 0;
  pLayerCfg.Backcolor.Red = 0;
  if (HAL_LTDC_ConfigLayer(&hltdc, &pLayerCfg, 0) != HAL_OK)
  {
    Error_Handler();
  }
  pLayerCfg1.WindowX0 = 0;
  pLayerCfg1.WindowX1 = 800;
  pLayerCfg1.WindowY0 = 0;
  pLayerCfg1.WindowY1 = 480;
  pLayerCfg1.PixelFormat = LTDC_PIXEL_FORMAT_ARGB8888;
  pLayerCfg1.Alpha = 0;
  pLayerCfg1.Alpha0 = 255;
  pLayerCfg1.BlendingFactor1 = LTDC_BLENDING_FACTOR1_CA;
  pLayerCfg1.BlendingFactor2 = LTDC_BLENDING_FACTOR2_CA;
  pLayerCfg1.FBStartAdress = 0;
  pLayerCfg1.ImageWidth = 0;
  pLayerCfg1.ImageHeight = 0;
  pLayerCfg1.Backcolor.Blue = 0;
  pLayerCfg1.Backcolor.Green = 0;
  pLayerCfg1.Backcolor.Red = 0;
  if (HAL_LTDC_ConfigLayer(&hltdc, &pLayerCfg1, 1) != HAL_OK)
  {
    Error_Handler();
  }

}

static void MX_QUADSPI_Init(void)
{

  /* QUADSPI parameter configuration*/
  hqspi.Instance = QUADSPI;
  hqspi.Init.ClockPrescaler = 255;
  hqspi.Init.FifoThreshold = 1;
  hqspi.Init.SampleShifting = QSPI_SAMPLE_SHIFTING_NONE;
  hqspi.Init.FlashSize = 1;
  hqspi.Init.ChipSelectHighTime = QSPI_CS_HIGH_TIME_1_CYCLE;
  hqspi.Init.ClockMode = QSPI_CLOCK_MODE_0;
  hqspi.Init.FlashID = QSPI_FLASH_ID_1;
  hqspi.Init.DualFlash = QSPI_DUALFLASH_DISABLE;
  if (HAL_QSPI_Init(&hqspi) != HAL_OK)
  {
    Error_Handler();
  }

}

/* FMC initialization function */
static void MX_FMC_Init(void)
{

  FMC_SDRAM_TimingTypeDef SdramTiming = {0};

  /** Perform the SDRAM1 memory initialization sequence
  */
  hsdram1.Instance = FMC_SDRAM_DEVICE;
  /* hsdram1.Init */
  hsdram1.Init.SDBank = FMC_SDRAM_BANK1;
  hsdram1.Init.ColumnBitsNumber = FMC_SDRAM_COLUMN_BITS_NUM_8;
  hsdram1.Init.RowBitsNumber = FMC_SDRAM_ROW_BITS_NUM_13;
  hsdram1.Init.MemoryDataWidth = FMC_SDRAM_MEM_BUS_WIDTH_16;
  hsdram1.Init.InternalBankNumber = FMC_SDRAM_INTERN_BANKS_NUM_4;
  hsdram1.Init.CASLatency = FMC_SDRAM_CAS_LATENCY_1;
  hsdram1.Init.WriteProtection = FMC_SDRAM_WRITE_PROTECTION_DISABLE;
  hsdram1.Init.SDClockPeriod = FMC_SDRAM_CLOCK_DISABLE;
  hsdram1.Init.ReadBurst = FMC_SDRAM_RBURST_DISABLE;
  hsdram1.Init.ReadPipeDelay = FMC_SDRAM_RPIPE_DELAY_0;
  /* SdramTiming */
  SdramTiming.LoadToActiveDelay = 16;
  SdramTiming.ExitSelfRefreshDelay = 16;
  SdramTiming.SelfRefreshTime = 16;
  SdramTiming.RowCycleDelay = 16;
  SdramTiming.WriteRecoveryTime = 16;
  SdramTiming.RPDelay = 16;
  SdramTiming.RCDDelay = 16;

  if (HAL_SDRAM_Init(&hsdram1, &SdramTiming) != HAL_OK)
  {
    Error_Handler( );
  }

}

static void MX_GPIO_Init(void)
{
  GPIO_InitTypeDef GPIO_InitStruct = {0};

  /* GPIO Ports Clock Enable */
  __HAL_RCC_GPIOE_CLK_ENABLE();
  __HAL_RCC_GPIOG_CLK_ENABLE();
  __HAL_RCC_GPIOB_CLK_ENABLE();
  __HAL_RCC_GPIOD_CLK_ENABLE();
  __HAL_RCC_GPIOC_CLK_ENABLE();
  __HAL_RCC_GPIOA_CLK_ENABLE();
  __HAL_RCC_GPIOJ_CLK_ENABLE();
  __HAL_RCC_GPIOI_CLK_ENABLE();
  __HAL_RCC_GPIOK_CLK_ENABLE();
  __HAL_RCC_GPIOF_CLK_ENABLE();
  __HAL_RCC_GPIOH_CLK_ENABLE();

  /*Configure GPIO pins : SAI1_FSA_Pin SAI1_SDB_Pin SAI1_SCKA_Pin SAI1_SDA_Pin */
  GPIO_InitStruct.Pin = SAI1_FSA_Pin|SAI1_SDB_Pin|SAI1_SCKA_Pin|SAI1_SDA_Pin;
  GPIO_InitStruct.Mode = GPIO_MODE_AF_PP;
  GPIO_InitStruct.Pull = GPIO_NOPULL;
  GPIO_InitStruct.Speed = GPIO_SPEED_FREQ_LOW;
  GPIO_InitStruct.Alternate = GPIO_AF6_SAI1;
  HAL_GPIO_Init(GPIOE, &GPIO_InitStruct);

  /*Configure GPIO pins : RMII_TXD1_Pin RMII_TXD0_Pin RMII_TX_EN_Pin */
  GPIO_InitStruct.Pin = RMII_TXD1_Pin|RMII_TXD0_Pin|RMII_TX_EN_Pin;
  GPIO_InitStruct.Mode = GPIO_MODE_AF_PP;
  GPIO_InitStruct.Pull = GPIO_NOPULL;
  GPIO_InitStruct.Speed = GPIO_SPEED_FREQ_VERY_HIGH;
  GPIO_InitStruct.Alternate = GPIO_AF11_ETH;
  HAL_GPIO_Init(GPIOG, &GPIO_InitStruct);

  /*Configure GPIO pins : ULPI_D7_Pin ULPI_D6_Pin ULPI_D5_Pin ULPI_D3_Pin
                           ULPI_D2_Pin ULPI_D1_Pin ULPI_D4_Pin */
  GPIO_InitStruct.Pin = ULPI_D7_Pin|ULPI_D6_Pin|ULPI_D5_Pin|ULPI_D3_Pin
                          |ULPI_D2_Pin|ULPI_D1_Pin|ULPI_D4_Pin;
  GPIO_InitStruct.Mode = GPIO_MODE_AF_PP;
  GPIO_InitStruct.Pull = GPIO_NOPULL;
  GPIO_InitStruct.Speed = GPIO_SPEED_FREQ_VERY_HIGH;
  GPIO_InitStruct.Alternate = GPIO_AF10_OTG_HS;
  HAL_GPIO_Init(GPIOB, &GPIO_InitStruct);

  /*Configure GPIO pins : uSD_D3_Pin uSD_D2_Pin */
  GPIO_InitStruct.Pin = uSD_D3_Pin|uSD_D2_Pin;
  GPIO_InitStruct.Mode = GPIO_MODE_AF_PP;
  GPIO_InitStruct.Pull = GPIO_NOPULL;
  GPIO_InitStruct.Speed = GPIO_SPEED_FREQ_VERY_HIGH;
  GPIO_InitStruct.Alternate = GPIO_AF10_SDMMC2;
  HAL_GPIO_Init(GPIOB, &GPIO_InitStruct);

  /*Configure GPIO pins : uSD_CMD_Pin uSD_CLK_Pin */
  GPIO_InitStruct.Pin = uSD_CMD_Pin|uSD_CLK_Pin;
  GPIO_InitStruct.Mode = GPIO_MODE_AF_PP;
  GPIO_InitStruct.Pull = GPIO_NOPULL;
  GPIO_InitStruct.Speed = GPIO_SPEED_FREQ_VERY_HIGH;
  GPIO_InitStruct.Alternate = GPIO_AF11_SDMMC2;
  HAL_GPIO_Init(GPIOD, &GPIO_InitStruct);

  /*Configure GPIO pin : WIFI_RX_Pin */
  GPIO_InitStruct.Pin = WIFI_RX_Pin;
  GPIO_InitStruct.Mode = GPIO_MODE_AF_PP;
  GPIO_InitStruct.Pull = GPIO_NOPULL;
  GPIO_InitStruct.Speed = GPIO_SPEED_FREQ_VERY_HIGH;
  GPIO_InitStruct.Alternate = GPIO_AF8_UART5;
  HAL_GPIO_Init(WIFI_RX_GPIO_Port, &GPIO_InitStruct);

  /*Configure GPIO pin : CEC_Pin */
  GPIO_InitStruct.Pin = CEC_Pin;
  GPIO_InitStruct.Mode = GPIO_MODE_AF_OD;
  GPIO_InitStruct.Pull = GPIO_NOPULL;
  GPIO_InitStruct.Speed = GPIO_SPEED_FREQ_LOW;
  GPIO_InitStruct.Alternate = GPIO_AF4_CEC;
  HAL_GPIO_Init(CEC_GPIO_Port, &GPIO_InitStruct);

  /*Configure GPIO pin : AUDIO_SDA_Pin */
  GPIO_InitStruct.Pin = AUDIO_SDA_Pin;
  GPIO_InitStruct.Mode = GPIO_MODE_AF_OD;
  GPIO_InitStruct.Pull = GPIO_PULLUP;
  GPIO_InitStruct.Speed = GPIO_SPEED_FREQ_VERY_HIGH;
  GPIO_InitStruct.Alternate = GPIO_AF11_I2C4;
  HAL_GPIO_Init(AUDIO_SDA_GPIO_Port, &GPIO_InitStruct);

  /*Configure GPIO pins : LD_USER1_Pin Audio_INT_Pin WIFI_RST_Pin DSI_RESET_Pin
                           ARD_D8_Pin LD_USER2_Pin ARD_D7_Pin ARD_D4_Pin
                           ARD_D2_Pin */
  GPIO_InitStruct.Pin = LD_USER1_Pin|Audio_INT_Pin|WIFI_RST_Pin|DSI_RESET_Pin
                          |ARD_D8_Pin|LD_USER2_Pin|ARD_D7_Pin|ARD_D4_Pin
                          |ARD_D2_Pin;
  GPIO_InitStruct.Mode = GPIO_MODE_INPUT;
  GPIO_InitStruct.Pull = GPIO_NOPULL;
  HAL_GPIO_Init(GPIOJ, &GPIO_InitStruct);

  /*Configure GPIO pins : DFSDM_DATIN5_Pin DFSDM_DATIN1_Pin */
  GPIO_InitStruct.Pin = DFSDM_DATIN5_Pin|DFSDM_DATIN1_Pin;
  GPIO_InitStruct.Mode = GPIO_MODE_AF_PP;
  GPIO_InitStruct.Pull = GPIO_NOPULL;
  GPIO_InitStruct.Speed = GPIO_SPEED_FREQ_LOW;
  GPIO_InitStruct.Alternate = GPIO_AF3_DFSDM1;
  HAL_GPIO_Init(GPIOC, &GPIO_InitStruct);

  /*Configure GPIO pin : ARD_D13_SCK_Pin */
  GPIO_InitStruct.Pin = ARD_D13_SCK_Pin;
  GPIO_InitStruct.Mode = GPIO_MODE_AF_PP;
  GPIO_InitStruct.Pull = GPIO_NOPULL;
  GPIO_InitStruct.Speed = GPIO_SPEED_FREQ_LOW;
  GPIO_InitStruct.Alternate = GPIO_AF5_SPI2;
  HAL_GPIO_Init(ARD_D13_SCK_GPIO_Port, &GPIO_InitStruct);

  /*Configure GPIO pins : NC4_Pin NC5_Pin uSD_Detect_Pin LCD_BL_CTRL_Pin */
  GPIO_InitStruct.Pin = NC4_Pin|NC5_Pin|uSD_Detect_Pin|LCD_BL_CTRL_Pin;
  GPIO_InitStruct.Mode = GPIO_MODE_INPUT;
  GPIO_InitStruct.Pull = GPIO_NOPULL;
  HAL_GPIO_Init(GPIOI, &GPIO_InitStruct);

  /*Configure GPIO pins : NC3_Pin NC2_Pin NC1_Pin NC8_Pin
                           NC7_Pin */
  GPIO_InitStruct.Pin = NC3_Pin|NC2_Pin|NC1_Pin|NC8_Pin
                          |NC7_Pin;
  GPIO_InitStruct.Mode = GPIO_MODE_INPUT;
  GPIO_InitStruct.Pull = GPIO_NOPULL;
  HAL_GPIO_Init(GPIOK, &GPIO_InitStruct);

  /*Configure GPIO pin : SPDIF_RX_Pin */
  GPIO_InitStruct.Pin = SPDIF_RX_Pin;
  GPIO_InitStruct.Mode = GPIO_MODE_AF_PP;
  GPIO_InitStruct.Pull = GPIO_NOPULL;
  GPIO_InitStruct.Speed = GPIO_SPEED_FREQ_LOW;
  GPIO_InitStruct.Alternate = GPIO_AF7_SPDIFRX;
  HAL_GPIO_Init(SPDIF_RX_GPIO_Port, &GPIO_InitStruct);

  /*Configure GPIO pins : uSD_D1_Pin uSD_D0_Pin */
  GPIO_InitStruct.Pin = uSD_D1_Pin|uSD_D0_Pin;
  GPIO_InitStruct.Mode = GPIO_MODE_AF_PP;
  GPIO_InitStruct.Pull = GPIO_NOPULL;
  GPIO_InitStruct.Speed = GPIO_SPEED_FREQ_VERY_HIGH;
  GPIO_InitStruct.Alternate = GPIO_AF11_SDMMC2;
  HAL_GPIO_Init(GPIOG, &GPIO_InitStruct);

  /*Configure GPIO pins : RMII_RXER_Pin OTG_FS_OverCurrent_Pin */
  GPIO_InitStruct.Pin = RMII_RXER_Pin|OTG_FS_OverCurrent_Pin;
  GPIO_InitStruct.Mode = GPIO_MODE_INPUT;
  GPIO_InitStruct.Pull = GPIO_NOPULL;
  HAL_GPIO_Init(GPIOD, &GPIO_InitStruct);

  /*Configure GPIO pin : DFSDM_CKOUT_Pin */
  GPIO_InitStruct.Pin = DFSDM_CKOUT_Pin;
  GPIO_InitStruct.Mode = GPIO_MODE_AF_PP;
  GPIO_InitStruct.Pull = GPIO_NOPULL;
  GPIO_InitStruct.Speed = GPIO_SPEED_FREQ_LOW;
  GPIO_InitStruct.Alternate = GPIO_AF3_DFSDM1;
  HAL_GPIO_Init(DFSDM_CKOUT_GPIO_Port, &GPIO_InitStruct);

  /*Configure GPIO pin : SPI2_NSS_Pin */
  GPIO_InitStruct.Pin = SPI2_NSS_Pin;
  GPIO_InitStruct.Mode = GPIO_MODE_AF_PP;
  GPIO_InitStruct.Pull = GPIO_NOPULL;
  GPIO_InitStruct.Speed = GPIO_SPEED_FREQ_VERY_HIGH;
  GPIO_InitStruct.Alternate = GPIO_AF5_SPI2;
  HAL_GPIO_Init(SPI2_NSS_GPIO_Port, &GPIO_InitStruct);

  /*Configure GPIO pin : WIFI_TX_Pin */
  GPIO_InitStruct.Pin = WIFI_TX_Pin;
  GPIO_InitStruct.Mode = GPIO_MODE_AF_PP;
  GPIO_InitStruct.Pull = GPIO_NOPULL;
  GPIO_InitStruct.Speed = GPIO_SPEED_FREQ_VERY_HIGH;
  GPIO_InitStruct.Alternate = GPIO_AF8_UART5;
  HAL_GPIO_Init(WIFI_TX_GPIO_Port, &GPIO_InitStruct);

  /*Configure GPIO pin : VCP_RX_Pin */
  GPIO_InitStruct.Pin = VCP_RX_Pin;
  GPIO_InitStruct.Mode = GPIO_MODE_AF_PP;
  GPIO_InitStruct.Pull = GPIO_NOPULL;
  GPIO_InitStruct.Speed = GPIO_SPEED_FREQ_VERY_HIGH;
  GPIO_InitStruct.Alternate = GPIO_AF7_USART1;
  HAL_GPIO_Init(VCP_RX_GPIO_Port, &GPIO_InitStruct);

  /*Configure GPIO pin : VCP_TX_Pin */
  GPIO_InitStruct.Pin = VCP_TX_Pin;
  GPIO_InitStruct.Mode = GPIO_MODE_AF_PP;
  GPIO_InitStruct.Pull = GPIO_NOPULL;
  GPIO_InitStruct.Speed = GPIO_SPEED_FREQ_LOW;
  GPIO_InitStruct.Alternate = GPIO_AF7_USART1;
  HAL_GPIO_Init(VCP_TX_GPIO_Port, &GPIO_InitStruct);

  /*Configure GPIO pin : ULPI_DIR_Pin */
  GPIO_InitStruct.Pin = ULPI_DIR_Pin;
  GPIO_InitStruct.Mode = GPIO_MODE_AF_PP;
  GPIO_InitStruct.Pull = GPIO_NOPULL;
  GPIO_InitStruct.Speed = GPIO_SPEED_FREQ_VERY_HIGH;
  GPIO_InitStruct.Alternate = GPIO_AF10_OTG_HS;
  HAL_GPIO_Init(ULPI_DIR_GPIO_Port, &GPIO_InitStruct);

  /*Configure GPIO pin : CEC_CLK_Pin */
  GPIO_InitStruct.Pin = CEC_CLK_Pin;
  GPIO_InitStruct.Mode = GPIO_MODE_AF_PP;
  GPIO_InitStruct.Pull = GPIO_NOPULL;
  GPIO_InitStruct.Speed = GPIO_SPEED_FREQ_LOW;
  GPIO_InitStruct.Alternate = GPIO_AF0_MCO;
  HAL_GPIO_Init(CEC_CLK_GPIO_Port, &GPIO_InitStruct);

  /*Configure GPIO pin : LCD_INT_Pin */
  GPIO_InitStruct.Pin = LCD_INT_Pin;
  GPIO_InitStruct.Mode = GPIO_MODE_EVT_RISING;
  GPIO_InitStruct.Pull = GPIO_NOPULL;
  HAL_GPIO_Init(LCD_INT_GPIO_Port, &GPIO_InitStruct);

  /*Configure GPIO pin : ARD_D5_PWM_Pin */
  GPIO_InitStruct.Pin = ARD_D5_PWM_Pin;
  GPIO_InitStruct.Mode = GPIO_MODE_AF_PP;
  GPIO_InitStruct.Pull = GPIO_NOPULL;
  GPIO_InitStruct.Speed = GPIO_SPEED_FREQ_LOW;
  GPIO_InitStruct.Alternate = GPIO_AF2_TIM3;
  HAL_GPIO_Init(ARD_D5_PWM_GPIO_Port, &GPIO_InitStruct);

  /*Configure GPIO pins : ARD_D0_RX_Pin ARDUINO_TX_D1_Pin */
  GPIO_InitStruct.Pin = ARD_D0_RX_Pin|ARDUINO_TX_D1_Pin;
  GPIO_InitStruct.Mode = GPIO_MODE_AF_PP;
  GPIO_InitStruct.Pull = GPIO_NOPULL;
  GPIO_InitStruct.Speed = GPIO_SPEED_FREQ_VERY_HIGH;
  GPIO_InitStruct.Alternate = GPIO_AF8_USART6;
  HAL_GPIO_Init(GPIOC, &GPIO_InitStruct);

  /*Configure GPIO pin : ULPI_NXT_Pin */
  GPIO_InitStruct.Pin = ULPI_NXT_Pin;
  GPIO_InitStruct.Mode = GPIO_MODE_AF_PP;
  GPIO_InitStruct.Pull = GPIO_NOPULL;
  GPIO_InitStruct.Speed = GPIO_SPEED_FREQ_VERY_HIGH;
  GPIO_InitStruct.Alternate = GPIO_AF10_OTG_HS;
  HAL_GPIO_Init(ULPI_NXT_GPIO_Port, &GPIO_InitStruct);

  /*Configure GPIO pin : SAI1_MCLKA_Pin */
  GPIO_InitStruct.Pin = SAI1_MCLKA_Pin;
  GPIO_InitStruct.Mode = GPIO_MODE_AF_PP;
  GPIO_InitStruct.Pull = GPIO_NOPULL;
  GPIO_InitStruct.Speed = GPIO_SPEED_FREQ_LOW;
  GPIO_InitStruct.Alternate = GPIO_AF6_SAI1;
  HAL_GPIO_Init(SAI1_MCLKA_GPIO_Port, &GPIO_InitStruct);

  /*Configure GPIO pins : EXT_SDA_Pin EXT_SCL_Pin */
  GPIO_InitStruct.Pin = EXT_SDA_Pin|EXT_SCL_Pin;
  GPIO_InitStruct.Mode = GPIO_MODE_INPUT;
  GPIO_InitStruct.Pull = GPIO_NOPULL;
  HAL_GPIO_Init(GPIOG, &GPIO_InitStruct);

  /*Configure GPIO pin : ARD_D6_PWM_Pin */
  GPIO_InitStruct.Pin = ARD_D6_PWM_Pin;
  GPIO_InitStruct.Mode = GPIO_MODE_AF_PP;
  GPIO_InitStruct.Pull = GPIO_NOPULL;
  GPIO_InitStruct.Speed = GPIO_SPEED_FREQ_LOW;
  GPIO_InitStruct.Alternate = GPIO_AF3_TIM11;
  HAL_GPIO_Init(ARD_D6_PWM_GPIO_Port, &GPIO_InitStruct);

  /*Configure GPIO pin : ARD_D3_PWM_Pin */
  GPIO_InitStruct.Pin = ARD_D3_PWM_Pin;
  GPIO_InitStruct.Mode = GPIO_MODE_AF_PP;
  GPIO_InitStruct.Pull = GPIO_NOPULL;
  GPIO_InitStruct.Speed = GPIO_SPEED_FREQ_LOW;
  GPIO_InitStruct.Alternate = GPIO_AF3_TIM10;
  HAL_GPIO_Init(ARD_D3_PWM_GPIO_Port, &GPIO_InitStruct);

  /*Configure GPIO pins : ARDUINO_A1_Pin ARDUINO_A2_Pin ARDUINO_A3_Pin */
  GPIO_InitStruct.Pin = ARDUINO_A1_Pin|ARDUINO_A2_Pin|ARDUINO_A3_Pin;
  GPIO_InitStruct.Mode = GPIO_MODE_ANALOG;
  GPIO_InitStruct.Pull = GPIO_NOPULL;
  HAL_GPIO_Init(GPIOF, &GPIO_InitStruct);

  /*Configure GPIO pin : ULPI_STP_Pin */
  GPIO_InitStruct.Pin = ULPI_STP_Pin;
  GPIO_InitStruct.Mode = GPIO_MODE_AF_PP;
  GPIO_InitStruct.Pull = GPIO_NOPULL;
  GPIO_InitStruct.Speed = GPIO_SPEED_FREQ_VERY_HIGH;
  GPIO_InitStruct.Alternate = GPIO_AF10_OTG_HS;
  HAL_GPIO_Init(ULPI_STP_GPIO_Port, &GPIO_InitStruct);

  /*Configure GPIO pins : RMII_MDC_Pin RMII_RXD0_Pin RMII_RXD1_Pin */
  GPIO_InitStruct.Pin = RMII_MDC_Pin|RMII_RXD0_Pin|RMII_RXD1_Pin;
  GPIO_InitStruct.Mode = GPIO_MODE_AF_PP;
  GPIO_InitStruct.Pull = GPIO_NOPULL;
  GPIO_InitStruct.Speed = GPIO_SPEED_FREQ_VERY_HIGH;
  GPIO_InitStruct.Alternate = GPIO_AF11_ETH;
  HAL_GPIO_Init(GPIOC, &GPIO_InitStruct);

  /*Configure GPIO pin : ARD_A2_Pin */
  GPIO_InitStruct.Pin = ARD_A2_Pin;
  GPIO_InitStruct.Mode = GPIO_MODE_ANALOG;
  GPIO_InitStruct.Pull = GPIO_NOPULL;
  HAL_GPIO_Init(ARD_A2_GPIO_Port, &GPIO_InitStruct);

  /*Configure GPIO pin : AUDIO_SCL_Pin */
  GPIO_InitStruct.Pin = AUDIO_SCL_Pin;
  GPIO_InitStruct.Mode = GPIO_MODE_AF_OD;
  GPIO_InitStruct.Pull = GPIO_PULLUP;
  GPIO_InitStruct.Speed = GPIO_SPEED_FREQ_VERY_HIGH;
  GPIO_InitStruct.Alternate = GPIO_AF4_I2C4;
  HAL_GPIO_Init(AUDIO_SCL_GPIO_Port, &GPIO_InitStruct);

  /*Configure GPIO pins : RMII_REF_CLK_Pin RMII_MDIO_Pin RMII_CRS_DV_Pin */
  GPIO_InitStruct.Pin = RMII_REF_CLK_Pin|RMII_MDIO_Pin|RMII_CRS_DV_Pin;
  GPIO_InitStruct.Mode = GPIO_MODE_AF_PP;
  GPIO_InitStruct.Pull = GPIO_NOPULL;
  GPIO_InitStruct.Speed = GPIO_SPEED_FREQ_VERY_HIGH;
  GPIO_InitStruct.Alternate = GPIO_AF11_ETH;
  HAL_GPIO_Init(GPIOA, &GPIO_InitStruct);

  /*Configure GPIO pin : B_USER_Pin */
  GPIO_InitStruct.Pin = B_USER_Pin;
  GPIO_InitStruct.Mode = GPIO_MODE_IT_RISING;
  GPIO_InitStruct.Pull = GPIO_NOPULL;
  HAL_GPIO_Init(B_USER_GPIO_Port, &GPIO_InitStruct);

  /*Configure GPIO pins : ARD_A1_Pin ARD_A0_Pin */
  GPIO_InitStruct.Pin = ARD_A1_Pin|ARD_A0_Pin;
  GPIO_InitStruct.Mode = GPIO_MODE_ANALOG;
  GPIO_InitStruct.Pull = GPIO_NOPULL;
  HAL_GPIO_Init(GPIOA, &GPIO_InitStruct);

  /*Configure GPIO pin : SPDIF_TX_Pin */
  GPIO_InitStruct.Pin = SPDIF_TX_Pin;
  GPIO_InitStruct.Mode = GPIO_MODE_AF_PP;
  GPIO_InitStruct.Pull = GPIO_NOPULL;
  GPIO_InitStruct.Speed = GPIO_SPEED_FREQ_LOW;
  GPIO_InitStruct.Alternate = GPIO_AF10_SAI2;
  HAL_GPIO_Init(SPDIF_TX_GPIO_Port, &GPIO_InitStruct);

  /*Configure GPIO pin : EXT_RST_Pin */
  GPIO_InitStruct.Pin = EXT_RST_Pin;
  GPIO_InitStruct.Mode = GPIO_MODE_INPUT;
  GPIO_InitStruct.Pull = GPIO_NOPULL;
  HAL_GPIO_Init(EXT_RST_GPIO_Port, &GPIO_InitStruct);

  /*Configure GPIO pins : ULPI_CLK_Pin ULPI_D0_Pin */
  GPIO_InitStruct.Pin = ULPI_CLK_Pin|ULPI_D0_Pin;
  GPIO_InitStruct.Mode = GPIO_MODE_AF_PP;
  GPIO_InitStruct.Pull = GPIO_NOPULL;
  GPIO_InitStruct.Speed = GPIO_SPEED_FREQ_VERY_HIGH;
  GPIO_InitStruct.Alternate = GPIO_AF10_OTG_HS;
  HAL_GPIO_Init(GPIOA, &GPIO_InitStruct);

  /*Configure GPIO pin : ARDUINO_PWM_D6_Pin */
  GPIO_InitStruct.Pin = ARDUINO_PWM_D6_Pin;
  GPIO_InitStruct.Mode = GPIO_MODE_AF_PP;
  GPIO_InitStruct.Pull = GPIO_NOPULL;
  GPIO_InitStruct.Speed = GPIO_SPEED_FREQ_LOW;
  GPIO_InitStruct.Alternate = GPIO_AF9_TIM12;
  HAL_GPIO_Init(ARDUINO_PWM_D6_GPIO_Port, &GPIO_InitStruct);

  /*Configure GPIO pins : ARDUINO_MISO_D12_Pin ARDUINO_MOSI_PWM_D11_Pin */
  GPIO_InitStruct.Pin = ARDUINO_MISO_D12_Pin|ARDUINO_MOSI_PWM_D11_Pin;
  GPIO_InitStruct.Mode = GPIO_MODE_AF_PP;
  GPIO_InitStruct.Pull = GPIO_NOPULL;
  GPIO_InitStruct.Speed = GPIO_SPEED_FREQ_LOW;
  GPIO_InitStruct.Alternate = GPIO_AF5_SPI2;
  HAL_GPIO_Init(GPIOB, &GPIO_InitStruct);

  /* EXTI interrupt init*/
  HAL_NVIC_SetPriority(EXTI0_IRQn, 0, 0);
  HAL_NVIC_EnableIRQ(EXTI0_IRQn);

}

void HAL_TIM_PeriodElapsedCallback(TIM_HandleTypeDef *htim)
{
  if (htim->Instance == TIM6) {
    HAL_IncTick();
  }
}

void Error_Handler(void)
{
}

/************************ (C) COPYRIGHT STMicroelectronics *****END OF FILE****/
